# soc register map
Vendor: litex
Litex SoC 2022-01-07 04:20:29
Registers are 32-bit, read-write, reset 0x0 unless marked. A register's access mark holds for its fields unless they carry their own. Offsets are from the block's base; lines under a group give offsets from that group; [hi:lo] are bit positions; {n}, {i} and the like mark numbered series; 'fields as' and 'values as' point back to an identical list; <NAME> marks a mode.

## Memory map
0xF0000000 GPU size 0xC
0xF0000800 CTRL size 0xC
0xF0001000 ETHPHY size 0x10
0xF0001800 IDENTIFIER_MEM size 0x4
0xF0002000 SDRAM size 0x1C
0xF0002800 TIMER0 size 0x20
0xF0003000 UART size 0x20

## Further device data
memoryRegions:
  SRAM baseAddress=0x01000000 size=0x00002000
  MAIN_RAM baseAddress=0x40000000 size=0x00400000
  EXTMEM baseAddress=0x00000000 size=0x00080000
  WBRAM baseAddress=0x00080000 size=0x00000800
  CSR baseAddress=0xF0000000 size=0x00010000
constants:
  CONFIG_CLOCK_FREQUENCY value=60000000
  CONFIG_CPU_TYPE_NONE value=None
  CONFIG_CPU_VARIANT_STANDARD value=None
  CONFIG_CPU_HUMAN_NAME value=Unknown
  CONFIG_WITH_BUILD_TIME value=None
  UART_POLLING value=None
  CONFIG_L2_SIZE value=8192
  CONFIG_CSR_DATA_WIDTH value=32
  CONFIG_CSR_ALIGNMENT value=32
  CONFIG_BUS_STANDARD value=WISHBONE
  CONFIG_BUS_DATA_WIDTH value=32
  CONFIG_BUS_ADDRESS_WIDTH value=32

## GPU
Base 0xF0000000
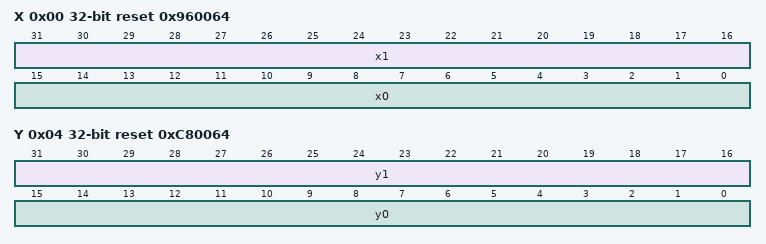
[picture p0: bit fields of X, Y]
0x00 X reset 0x960064 — X Coordinates
  [31:16] x1 — Right
  [15:0] x0 — Left
0x04 Y reset 0xC80064 — Y Coordinates
  [31:16] y1 — Bottom
  [15:0] y0 — Top
0x08 FRAME — Current Video Frame Number
  [15:0] frame

## CTRL
Base 0xF0000800
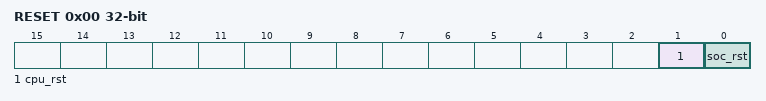
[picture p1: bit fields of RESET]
0x00 RESET
  [1] cpu_rst — Write `1` to this register to reset the CPU(s) of the SoC (Hold Reset)
  [0] soc_rst — Write `1` to this register to reset the full SoC (Pulse Reset)
0x04 SCRATCH reset 0x12345678 — Use this register as a scratch space to verify that software read/write accesses to the Wishbone/CSR bus are working correctly. The initial reset value of 0x1234578 can be used to verify endianness.
0x08 BUS_ERRORS — Total number of Wishbone bus errors (timeouts) since start.

## ETHPHY
Base 0xF0001000
0x00 CRG_RESET
  [0] crg_reset
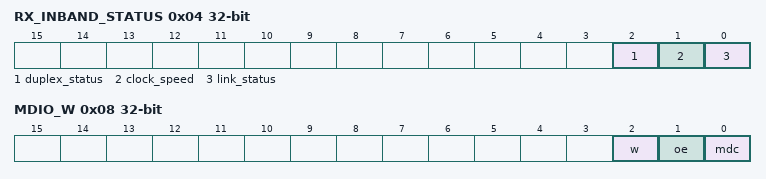
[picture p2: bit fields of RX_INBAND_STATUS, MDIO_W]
0x04 RX_INBAND_STATUS
  [2] duplex_status, [1] clock_speed, [0] link_status
0x08 MDIO_W
  [2] w, [1] oe, [0] mdc
0x0C MDIO_R
  [0] r

## IDENTIFIER_MEM
Base 0xF0001800
0x00 IDENTIFIER_MEM — 8 x 51-bit memory
  [7:0] identifier_mem

## SDRAM
Base 0xF0002000
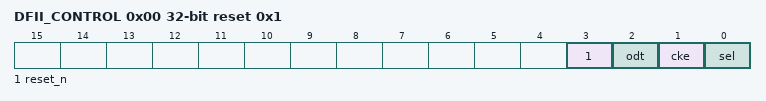
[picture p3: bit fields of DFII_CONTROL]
0x00 DFII_CONTROL reset 0x1
  [3] reset_n, [2] odt, [1] cke, [0] sel
0x04 DFII_PI0_COMMAND
  [5:0] dfii_pi0_command
0x08 DFII_PI0_COMMAND_ISSUE
  [0] dfii_pi0_command_issue
0x0C DFII_PI0_ADDRESS
  [10:0] dfii_pi0_address
0x10 DFII_PI0_BADDRESS
  [0] dfii_pi0_baddress
0x14 DFII_PI0_WRDATA
0x18 DFII_PI0_RDDATA

## TIMER0
Base 0xF0002800
0x00 LOAD — Load value when Timer is (re-)enabled. In One-Shot mode, the value written to this register specifies the Timer's duration in clock cycles.
0x04 RELOAD — Reload value when Timer reaches ``0``. In Periodic mode, the value written to this register specify the Timer's period in clock cycles.
0x08 EN — Enable flag of the Timer. Set this flag to ``1`` to enable/start the Timer. Set to ``0`` to disable the Timer.
  [0] en
0x0C UPDATE_VALUE — Update trigger for the current countdown value. A write to this register latches the current countdown value to ``value`` register.
  [0] update_value
0x10 VALUE — Latched countdown value. This value is updated by writing to ``update_value``.
0x14 EV_STATUS — This register contains the current raw level of the zero event trigger. Writes to this register have no effect.
  [0] zero — Level of the ``zero`` event
0x18 EV_PENDING — When a zero event occurs, the corresponding bit will be set in this register. To clear the Event, set the corresponding bit in this register.
  [0] zero — `1` if a `zero` event occurred. This Event is triggered on a **falling** edge.
0x1C EV_ENABLE — This register enables the corresponding zero events. Write a ``0`` to this register to disable individual events.
  [0] zero — Write a ``1`` to enable the ``zero`` Event

## UART
Base 0xF0003000
0x00 RXTX
  [7:0] rxtx
0x04 TXFULL — TX FIFO Full.
  [0] txfull
0x08 RXEMPTY — RX FIFO Empty.
  [0] rxempty
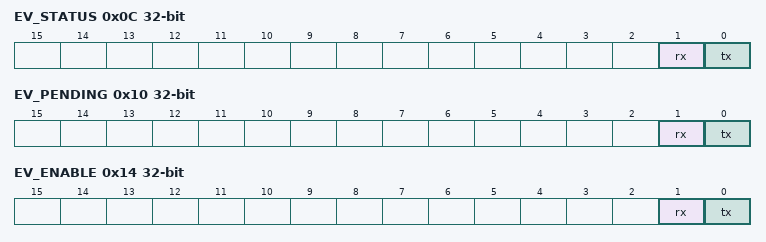
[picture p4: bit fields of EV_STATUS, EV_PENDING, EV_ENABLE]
0x0C EV_STATUS — This register contains the current raw level of the rx event trigger. Writes to this register have no effect.
  [1] rx — Level of the ``rx`` event
  [0] tx — Level of the ``tx`` event
0x10 EV_PENDING — When a rx event occurs, the corresponding bit will be set in this register. To clear the Event, set the corresponding bit in this register.
  [1] rx — `1` if a `rx` event occurred. This Event is triggered on a **falling** edge.
  [0] tx — `1` if a `tx` event occurred. This Event is triggered on a **falling** edge.
0x14 EV_ENABLE — This register enables the corresponding rx events. Write a ``0`` to this register to disable individual events.
  [1] rx — Write a ``1`` to enable the ``rx`` Event
  [0] tx — Write a ``1`` to enable the ``tx`` Event
0x18 TXEMPTY — TX FIFO Empty.
  [0] txempty
0x1C RXFULL — RX FIFO Full.
  [0] rxfull
